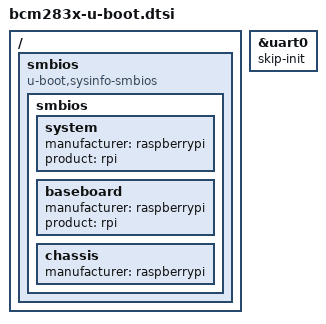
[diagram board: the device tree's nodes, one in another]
// SPDX-License-Identifier: GPL-2.0+
/*
 * U-Boot addition to keep baudrate set by firmware
 * and also initialize before relocation.
 *
 * (C) Copyright 2016 Fabian Vogt <fvogt@suse.com>
 */

/ {
	smbios {
		compatible = "u-boot,sysinfo-smbios";
		smbios {
			system {
				manufacturer = "raspberrypi";
				product = "rpi";
			};
			baseboard {
				manufacturer = "raspberrypi";
				product = "rpi";
			};
			chassis {
				manufacturer = "raspberrypi";
			};
		};
	};
};

&uart0 {
	skip-init;
	bootph-all;
};
